# ADuCM302x register map
Vendor: Analog Devices; Series: ADuCM302x; File version: 1p0
CPU: CM3 r0p1, little endian, no MPU, no FPU, 3 interrupt priority bits
Registers are 32-bit, read-write, reset 0x0 unless marked. A register's access mark holds for its fields unless they carry their own. Offsets are from the block's base; [hi:lo] are bit positions; {n}, {i} and the like mark numbered series.

## ADC0
Base 0x40007000
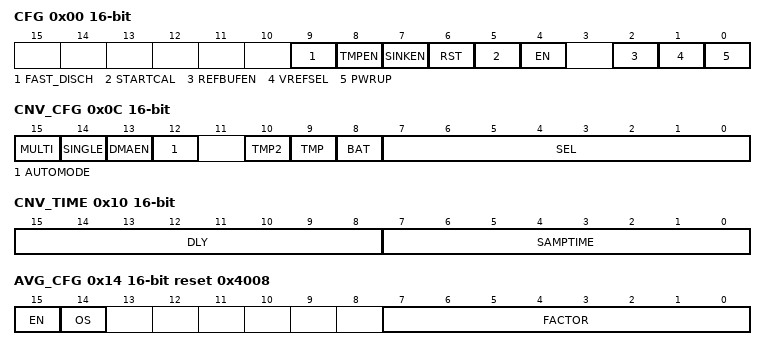
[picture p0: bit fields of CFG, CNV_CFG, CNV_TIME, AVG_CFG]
0x00 CFG 16-bit — ADC Configuration
  [9] FAST_DISCH range 0x00000000..0x00000001 — Fast Switchover of Vref from 2.5 to 1.25
  [8] TMPEN range 0x00000000..0x00000001 — Power up Temperature Sensor
  [7] SINKEN range 0x00000000..0x00000001 — Enable Additional Sink Current Capability
  [6] RST range 0x00000000..0x00000001 — Reset
  [5] STARTCAL range 0x00000000..0x00000001 — Start a New Offset Calibration Cycle
  [4] EN range 0x00000000..0x00000001 — Enable ADC Subsystem
  [2] REFBUFEN — Enable Internal Reference Buffer
    0=EXT_REF (External reference is used); 1=BUF_REF (Reference buffer is enabled)
  [1] VREFSEL — Select Vref as 1.25V or 2.5V
    0=V_2p5 (Vref = 2.5V); 1=V_1p25 (Vref = 1.25V)
  [0] PWRUP range 0x00000000..0x00000001 — Powering up the ADC
0x04 PWRUP 16-bit reset 0x20E — ADC Power-up Time
  [9:0] WAIT range 0x00000000..0x000003FF — Program This with 526/PCLKDIVCNT
0x08 CAL_WORD 16-bit reset 0x40 — Calibration Word
  [6:0] VALUE range 0x00000000..0x0000007F — Offset Calibration Word
0x0C CNV_CFG 16-bit — ADC Conversion Configuration
  [15] MULTI range 0x00000000..0x00000001 — Multiple Conversions
  [14] SINGLE range 0x00000000..0x00000001 — Single Conversion Start
  [13] DMAEN range 0x00000000..0x00000001 — DMA Channel Enable
  [12] AUTOMODE range 0x00000000..0x00000001 — Auto Mode Enable
  [10] TMP2 range 0x00000000..0x00000001 — Temperature Measurement 2
  [9] TMP range 0x00000000..0x00000001 — Temperature Measurement 1
  [8] BAT range 0x00000000..0x00000001 — Battery Monitoring Enable
  [7:0] SEL range 0x00000000..0x000000FF — Selection of Channel(s) to Convert
0x10 CNV_TIME 16-bit — ADC Conversion Time
  [15:8] DLY range 0x00000000..0x000000FF — Delay Between Two Consecutive Conversions
  [7:0] SAMPTIME range 0x00000000..0x000000FF — Sampling Time
0x14 AVG_CFG 16-bit reset 0x4008 — Averaging Configuration
  [15] EN range 0x00000000..0x00000001 — Enable Averaging on Channels Enabled in Enable Register
  [14] OS range 0x00000000..0x00000001 — Enable Oversampling
  [7:0] FACTOR range 0x00000000..0x000000FF — Averaging Factor
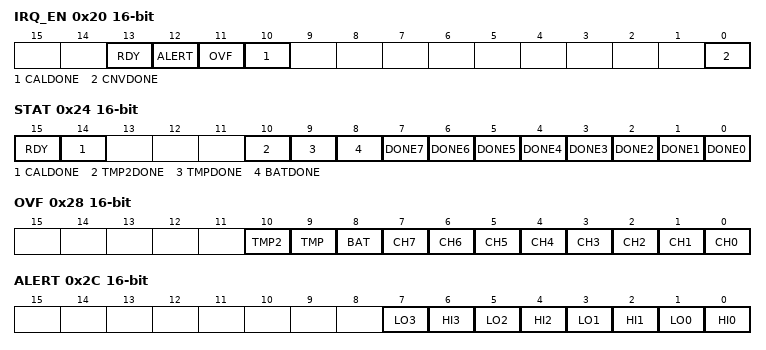
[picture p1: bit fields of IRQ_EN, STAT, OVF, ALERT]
0x20 IRQ_EN 16-bit — Interrupt Enable
  [13] RDY range 0x00000000..0x00000001 — Set to Enable Interrupt When ADC is Ready to Convert
  [12] ALERT range 0x00000000..0x00000001 — Interrupt on Crossing Lower or Higher Limit Enable
  [11] OVF range 0x00000000..0x00000001 — Enable Overflow Interrupt
  [10] CALDONE range 0x00000000..0x00000001 — Enable Interrupt for Calibration Done
  [0] CNVDONE range 0x00000000..0x00000001 — Enable Conversion Done Interrupt
0x24 STAT 16-bit — ADC Status
  [15] RDY range 0x00000000..0x00000001 — ADC Ready to Start Converting
  [14] CALDONE range 0x00000000..0x00000001 — Calibration Done
  [10] TMP2DONE range 0x00000000..0x00000001 — Conversion Done for Temperature Sensing 2
  [9] TMPDONE range 0x00000000..0x00000001 — Conversion Done for Temperature Sensing
  [8] BATDONE range 0x00000000..0x00000001 — Conversion Done - Battery Monitoring
  [n] DONE{n} range 0x00000000..0x00000001 (n=0..7) — Conversion Done on Channel {n}
0x28 OVF 16-bit — Overflow of Output Registers
  [10] TMP2 range 0x00000000..0x00000001 — Overflow in TMP2_OUT
  [9] TMP range 0x00000000..0x00000001 — Overflow in TMP_OUT
  [8] BAT range 0x00000000..0x00000001 — Overflow in BAT_OUT
  [n] CH{n} range 0x00000000..0x00000001 (n=0..7) — Overflow in CH{n}_OUT
0x2C ALERT 16-bit — Alert Indication
  [2n+1] LO{n} range 0x00000000..0x00000001 (n=0..3) — Channel {n} Low Alert Status
  [2n] HI{n} range 0x00000000..0x00000001 (n=0..3) — Channel {n} High Alert Status
{0x30+4i} CH{i}_OUT 16-bit (i=0..7) — Conversion Result Channel {i}
  [15:0] RESULT ro — Conversion Result of Channel {i}
0x50 BAT_OUT 16-bit — Battery Monitoring Result
  [15:0] RESULT ro — Conversion Result of Battery Monitoring
0x54 TMP_OUT 16-bit — Temperature Result
  [15:0] RESULT ro — Conversion Result of Temperature Measurement 1
0x58 TMP2_OUT 16-bit — Temperature Result 2
  [15:0] RESULT ro — Conversion Result of Temperature Measurement 2
0x5C DMA_OUT 16-bit — DMA Output Register
  [15:0] RESULT ro — Conversion Result for DMA
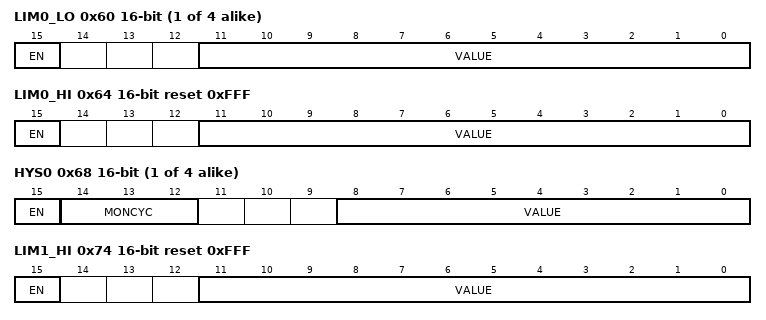
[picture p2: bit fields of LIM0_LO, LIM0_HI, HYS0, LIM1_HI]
{0x60+0x10*i} LIM{i}_LO 16-bit (i=0..3) — Channel {i} Low Limit
  [15] EN range 0x00000000..0x00000001 — Enable Low Limit Comparison on Channel {i}
  [11:0] VALUE range 0x00000000..0x00000FFF — Low Limit for Channel {i}
0x64 LIM0_HI 16-bit reset 0xFFF — Channel 0 High Limit
  [15] EN range 0x00000000..0x00000001 — Enable High Limit Comparison on Channel 0
  [11:0] VALUE range 0x00000000..0x00000FFF — High Limit for Channel 0
{0x68+0x10*i} HYS{i} 16-bit (i=0..3) — Channel {i} Hysteresis
  [15] EN range 0x00000000..0x00000001 — Enable Hysteresis for Comparison on Channel {i}
  [14:12] MONCYC range 0x00000000..0x00000007 — Number of Conversion Cycles to Monitor Channel {i}
  [8:0] VALUE range 0x00000000..0x000001FF — Hysteresis Value for Channel {i}
0x74 LIM1_HI 16-bit reset 0xFFF — Channel 1 High Limit
  [15] EN range 0x00000000..0x00000001 — Enable High Limit Comparison on Channel 1
  [11:0] VALUE range 0x00000000..0x00000FFF — High Limit for Channel 1
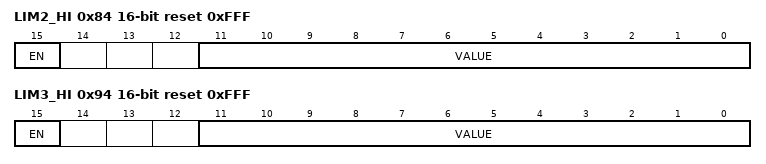
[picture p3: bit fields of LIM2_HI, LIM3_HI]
0x84 LIM2_HI 16-bit reset 0xFFF — Channel 2 High Limit
  [15] EN range 0x00000000..0x00000001 — Enable High Limit Comparison on Channel
  [11:0] VALUE range 0x00000000..0x00000FFF — High Limit for Channel 2
0x94 LIM3_HI 16-bit reset 0xFFF — Channel 3 High Limit
  [15] EN range 0x00000000..0x00000001 — Enable High Limit Comparison on Channel 3
  [11:0] VALUE range 0x00000000..0x00000FFF — High Limit for Channel 3
0xC0 CFG1 16-bit reset 0x400 — Reference Buffer Low Power Mode
  [0] RBUFLP range 0x00000000..0x00000001 — Enable Low Power Mode for Reference Buffer
